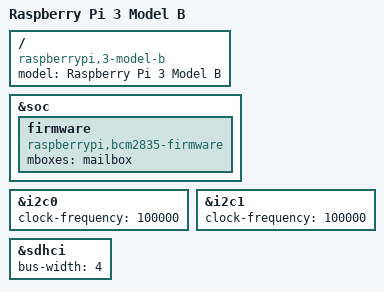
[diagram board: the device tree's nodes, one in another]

/include/ "bcm2837.dtsi"

/ {
	compatible = "raspberrypi,3-model-b", "brcm,bcm2837";
	model = "Raspberry Pi 3 Model B";
};

&soc {
	firmware: firmware {
		compatible = "raspberrypi,bcm2835-firmware";
		mboxes = <&mailbox>;
	};
};

&i2c0 {
	status = "okay";
	clock-frequency = <100000>;
};

&i2c1 {
	status = "okay";
	clock-frequency = <100000>;
};

&sdhci {
	status = "okay";
	bus-width = <4>;
};
